# haltium_bbpr register map
Vendor: Nordic Semiconductor; Series: nRFHaltium; File version: 1
Registers are 32-bit, read-write, reset 0x0 unless marked. A register's access mark holds for its fields unless they carry their own. Offsets are from the block's base; [hi:lo] are bit positions; lines under a group give offsets from that group; {n}, {i} and the like mark numbered series; 'fields as' and 'values as' point back to an identical list.

## GLOBAL_I3CCORE0_NS (part 2 of 2) — I3CCORE 0
Base 0x2FBE0000
Same registers: GLOBAL_I3CCORE1_NS 0x2FBE1000, GLOBAL_I3CCORE2_NS 0x2FBE2000, GLOBAL_I3CCORE3_NS 0x2FBE3000
0x900 DMA group — Unspecified
  0x00 CH0 group — Unspecified
    0x00 SAR0 64-bit — This register contains the source address of the DMA transfer.
      [31:0] SAR — Current Source Address of DMA transfer.
    0x08 DAR0 64-bit — This register contains the destination address of the DMA transfer.
      [31:0] DAR — Current Destination address of DMA transfer.
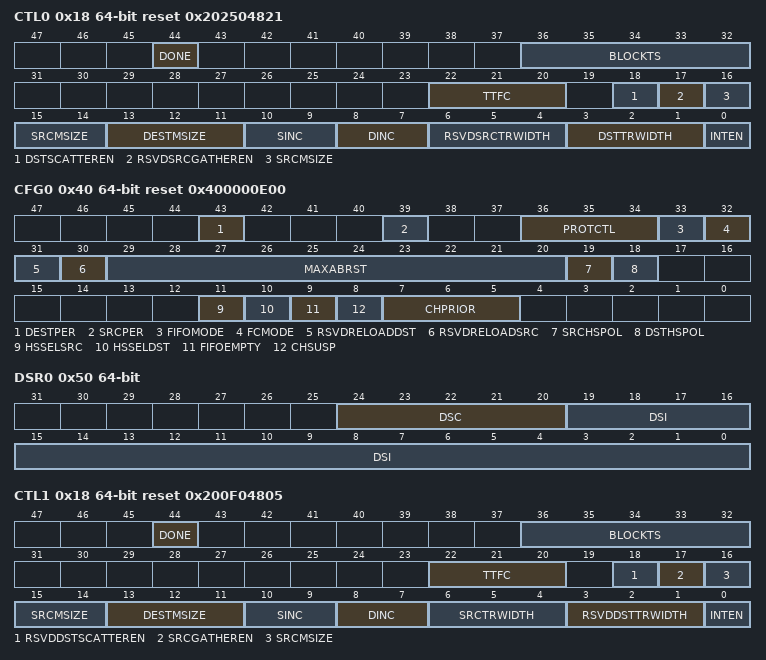
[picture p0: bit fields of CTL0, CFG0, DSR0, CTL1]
    0x18 CTL0 64-bit reset 0x202504821 (reset mask 0xFFFFFFFF) — This register contains fields that control the DMA transfer.
      [44] DONE — Done bit.
        0=DISABLED (Unspecified); 1=ENABLED (Unspecified)
      [36:32] BLOCKTS — Block Transfer Size.
      [22:20] TTFC — Transfer Type and Flow Control.
        {v}=TT_FC_{v} (Unspecified) (v=0..7)
      [18] DSTSCATTEREN — Destination scatter enable.
        0=DST_SCATTER_DISABLE (Unspecified); 1=DST_SCATTER_ENABLE (Unspecified)
      [17] RSVDSRCGATHEREN ro — Reserved field - read-only
      [16:14] SRCMSIZE — Source Burst Transaction Length.
        {v}=SRC_MSIZE_{v} (Unspecified) (v=0..7)
      [13:11] DESTMSIZE — Destination Burst Transaction Length.
        {v}=DEST_MSIZE_{v} (Unspecified) (v=0..7)
      [10:9] SINC — Source Address Increment.
        {v}=Unspecified (v=0..3)
      [8:7] DINC — Destination Address Increment.
        {v}=Unspecified (v=0..3)
      [6:4] RSVDSRCTRWIDTH ro — Reserved field - read-only
      [3:1] DSTTRWIDTH — Destination Transfer Width.
        {v}=DST_TR_WIDTH_{v} (Unspecified) (v=0..7)
      [0] INTEN — Interrupt Enable Bit.
        0=INTERRUPT_DISABLE (Unspecified); 1=INTERRUPT_ENABLE (Unspecified)
    0x40 CFG0 64-bit reset 0x400000E00 (reset mask 0xFFFFFFFF) — This register contains fields that configure the DMA transfer.
      [43] DESTPER — Destination hardware interface.
      [39] SRCPER — Source Hardware Interface.
      [36:34] PROTCTL — Protection Control bits used to drive the AHB HPROT[3:1] bus.
      [33] FIFOMODE — FIFO Mode Select.
        0=FIFO_MODE_0 (Unspecified); 1=FIFO_MODE_1 (Unspecified)
      [32] FCMODE — Flow Control Mode.
        0=Unspecified; 1=Unspecified
      [31] RSVDRELOADDST ro — Reserved field- read-only
      [30] RSVDRELOADSRC ro — Reserved field - read-only
      [29:20] MAXABRST — Maximum AMBA Burst Length.
      [19] SRCHSPOL — Source Handshaking Interface Polarity.
        0=ACTIVE_HIGH (Unspecified); 1=ACTIVE_LOW (Unspecified)
      [18] DSTHSPOL — Destination Handshaking Interface Polarity.
        0=ACTIVE_HIGH (Unspecified); 1=ACTIVE_LOW (Unspecified)
      [11] HSSELSRC — Source Software or Hardware Handshaking Select.
        0=HARDWARE_HS (Unspecified); 1=SOFTWARE_HS (Unspecified)
      [10] HSSELDST — Destination Software or Hardware Handshaking Select.
        0=HARDWARE_HS (Unspecified); 1=SOFTWARE_HS (Unspecified)
      [9] FIFOEMPTY ro — Channel FIFO status.
        0=NOT_EMPTY (Unspecified); 1=EMPTY (Unspecified)
      [8] CHSUSP — Channel Suspend.
        0=NOT_SUSPENDED (Unspecified); 1=SUSPENDED (Unspecified)
      [7:5] CHPRIOR — Channel Priority.
        {v}=CH_PRIOR_{v} (Unspecified) (v=0..7)
    0x50 DSR0 64-bit — Destination Scatter register.
      [24:20] DSC — Destination Scatter Count.
      [19:0] DSI — Destination Scatter Interval.
  0x58 CH1 group — Unspecified
    0x00 SAR1 64-bit — This register contains the source address of the DMA transfer.
      [31:0] SAR — Current Source Address of DMA transfer.
    0x08 DAR1 64-bit — This register contains the destination address of the DMA transfer.
      [31:0] DAR — Current Destination address of DMA transfer.
    0x18 CTL1 64-bit reset 0x200F04805 (reset mask 0xFFFFFFFF) — This register contains fields that control the DMA transfer.
      [44] DONE — Done bit.
        0=DISABLED (Unspecified); 1=ENABLED (Unspecified)
      [36:32] BLOCKTS — Block Transfer Size.
      [22:20] TTFC — Transfer Type and Flow Control.
        {v}=TT_FC_{v} (Unspecified) (v=0..7)
      [18] RSVDDSTSCATTEREN ro — Reserved field - read-only
      [17] SRCGATHEREN — Source gather enable.
        0=SRC_GATHER_DISABLE (Unspecified); 1=SRC_GATHER_ENABLE (Unspecified)
      [16:14] SRCMSIZE — Source Burst Transaction Length.
        {v}=SRC_MSIZE_{v} (Unspecified) (v=0..7)
      [13:11] DESTMSIZE — Destination Burst Transaction Length.
        {v}=DEST_MSIZE_{v} (Unspecified) (v=0..7)
      [10:9] SINC — Source Address Increment.
        {v}=Unspecified (v=0..3)
      [8:7] DINC — Destination Address Increment.
        {v}=Unspecified (v=0..3)
      [6:4] SRCTRWIDTH — Source Transfer Width.
        {v}=SRC_TR_WIDTH_{v} (Unspecified) (v=0..7)
      [3:1] RSVDDSTTRWIDTH ro — Reserved field - read-only
      [0] INTEN — Interrupt Enable Bit.
        values as DMA.CH0.CTL0.INTEN
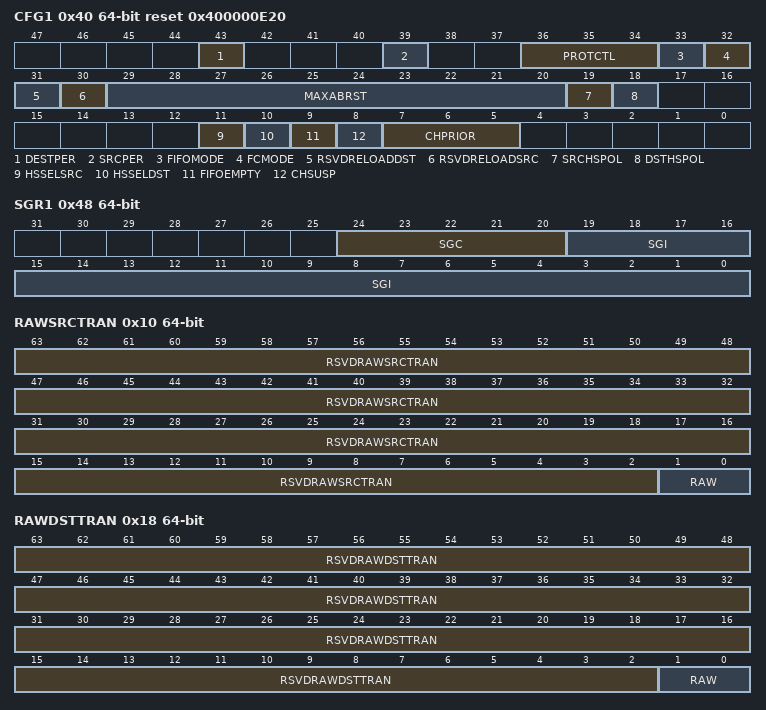
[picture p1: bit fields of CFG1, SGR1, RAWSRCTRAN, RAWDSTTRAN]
    0x40 CFG1 64-bit reset 0x400000E20 (reset mask 0xFFFFFFFF) — This register contains fields that configure the DMA transfer.
      fields as DMA.CH0.CFG0
    0x48 SGR1 64-bit — Source Gather register
      [24:20] SGC — Source Gather Count.
      [19:0] SGI — Source Gather Interval.
  0x2C0 INT group — Unspecified
    0x00 RAWTFR 64-bit — Interrupt events are stored in this Raw Interrupt Status register before masking.
      [1:0] RAW — Raw Status for IntTfr Interrupt
        0=INACTIVE (Unspecified); 1=ACTIVE (Unspecified)
    0x08 RAWBLOCK 64-bit — Interrupt events are stored in this Raw Interrupt Status register before masking.
      [1:0] RAW — Raw Status for IntBlock Interrupt
        0=INACTIVE (Unspecified); 1=ACTIVE (Unspecified)
    0x10 RAWSRCTRAN 64-bit (reset mask 0xFFFFFFFF) — Interrupt events are stored in this Raw Interrupt Status register before masking.
      [63:2] RSVDRAWSRCTRAN ro — Reserved field - read-only
      [1:0] RAW — Raw Status for IntSrcTran Interrupt
        0=INACTIVE (Unspecified); 1=ACTIVE (Unspecified)
    0x18 RAWDSTTRAN 64-bit (reset mask 0xFFFFFFFF) — Interrupt events are stored in this Raw Interrupt Status register before masking.
      [63:2] RSVDRAWDSTTRAN ro — Reserved field - read-only
      [1:0] RAW — Raw Status for IntDstTran Interrupt
        0=INACTIVE (Unspecified); 1=ACTIVE (Unspecified)
    0x20 RAWERR 64-bit — Interrupt events are stored in this Raw Interrupt Status register before masking.
      [1:0] RAW — Raw Status for IntErr Interrupt
        0=INACTIVE (Unspecified); 1=ACTIVE (Unspecified)
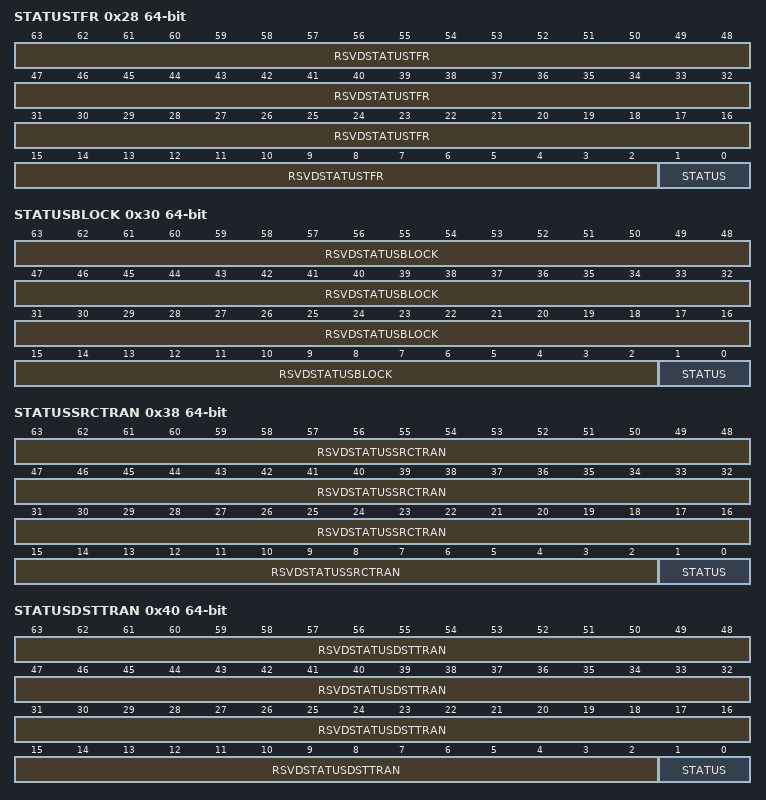
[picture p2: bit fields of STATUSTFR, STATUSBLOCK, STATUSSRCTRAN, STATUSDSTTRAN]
    0x28 STATUSTFR 64-bit (reset mask 0xFFFFFFFF) — Channel DMA Transfer complete interrupt event from all channels is stored in this Interrupt Status register after masking.
      [63:2] RSVDSTATUSTFR ro — Reserved field - read-only
      [1:0] STATUS ro — Status for IntTfr Interrupt
        0=INACTIVE (Unspecified); 1=ACTIVE (Unspecified)
    0x30 STATUSBLOCK 64-bit (reset mask 0xFFFFFFFF) — Channel Block complete interrupt event from all channels is stored in this Interrupt Status register after masking.
      [63:2] RSVDSTATUSBLOCK ro — Reserved field - read-only
      [1:0] STATUS ro — Status for IntBlock Interrupt
        0=INACTIVE (Unspecified); 1=ACTIVE (Unspecified)
    0x38 STATUSSRCTRAN 64-bit (reset mask 0xFFFFFFFF) — Channel Source Transaction complete interrupt event from all channels is stored in this Interrupt Status register after masking.
      [63:2] RSVDSTATUSSRCTRAN ro — Reserved field - read-only
      [1:0] STATUS ro — Status for IntSrcTran Interrupt
        0=INACTIVE (Unspecified); 1=ACTIVE (Unspecified)
    0x40 STATUSDSTTRAN 64-bit (reset mask 0xFFFFFFFF) — Channel destination transaction complete interrupt event from all channels is stored in this Interrupt Status register after masking.
      [63:2] RSVDSTATUSDSTTRAN ro — Reserved field - read-only
      [1:0] STATUS ro — Status for IntDstTran Interrupt
        0=INACTIVE (Unspecified); 1=ACTIVE (Unspecified)
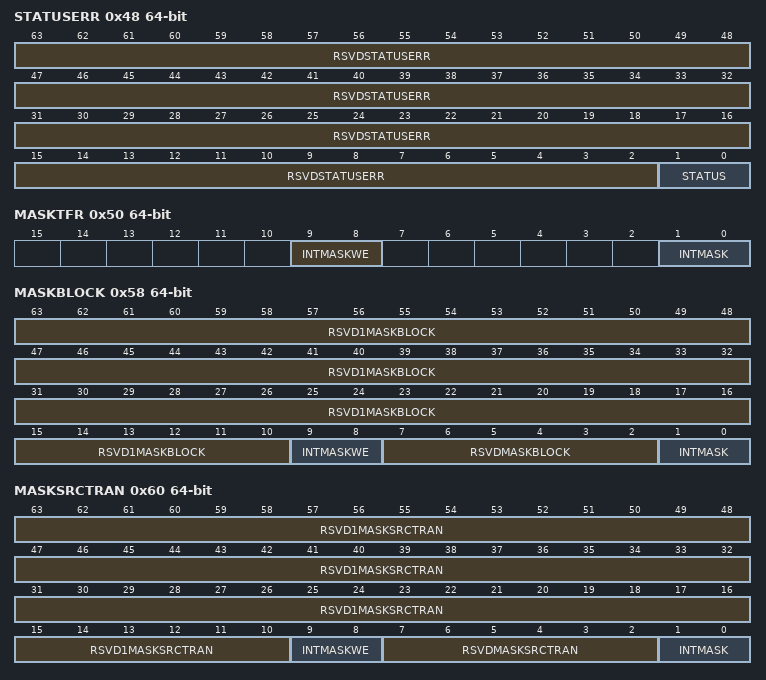
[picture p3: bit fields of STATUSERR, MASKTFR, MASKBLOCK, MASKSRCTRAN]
    0x48 STATUSERR 64-bit (reset mask 0xFFFFFFFF) — Channel Error interrupt event from all channels is stored in this Interrupt Status register after masking.
      [63:2] RSVDSTATUSERR ro — Reserved field - read-only
      [1:0] STATUS ro — Status for IntErr Interrupt
        0=INACTIVE (Unspecified); 1=ACTIVE (Unspecified)
    0x50 MASKTFR 64-bit — The contents of the Raw Status register RawTfr is masked with the contents of the Mask register MaskTfr.
      [9:8] INTMASKWE wo — Interrupt Mask Write Enable
        0=DISABLED (Unspecified); 1=ENABLED (Unspecified)
      [1:0] INTMASK — Mask for IntTfr Interrupt
        0=MASK (Unspecified); 1=UNMASK (Unspecified)
    0x58 MASKBLOCK 64-bit (reset mask 0xFFFFFFFF) — The contents of the Raw Status register RawBlock is masked with the contents of the Mask register MaskBlock.
      [63:10] RSVD1MASKBLOCK ro — Reserved field - read-only
      [9:8] INTMASKWE wo — Interrupt Mask Write Enable
        0=DISABLED (Unspecified); 1=ENABLED (Unspecified)
      [7:2] RSVDMASKBLOCK ro — Reserved field- read-only
      [1:0] INTMASK — Mask for IntBlock Interrupt
        0=MASK (Unspecified); 1=UNMASK (Unspecified)
    0x60 MASKSRCTRAN 64-bit (reset mask 0xFFFFFFFF) — The contents of the Raw Status register RawSrcTran is masked with the contents of the Mask register MaskSrcTran.
      [63:10] RSVD1MASKSRCTRAN ro — Reserved field - read-only
      [9:8] INTMASKWE wo — Interrupt Mask Write Enable
        0=DISABLED (Unspecified); 1=ENABLED (Unspecified)
      [7:2] RSVDMASKSRCTRAN ro — Reserved field- read-only
      [1:0] INTMASK — Mask for IntSrcTran Interrupt
        0=MASK (Unspecified); 1=UNMASK (Unspecified)
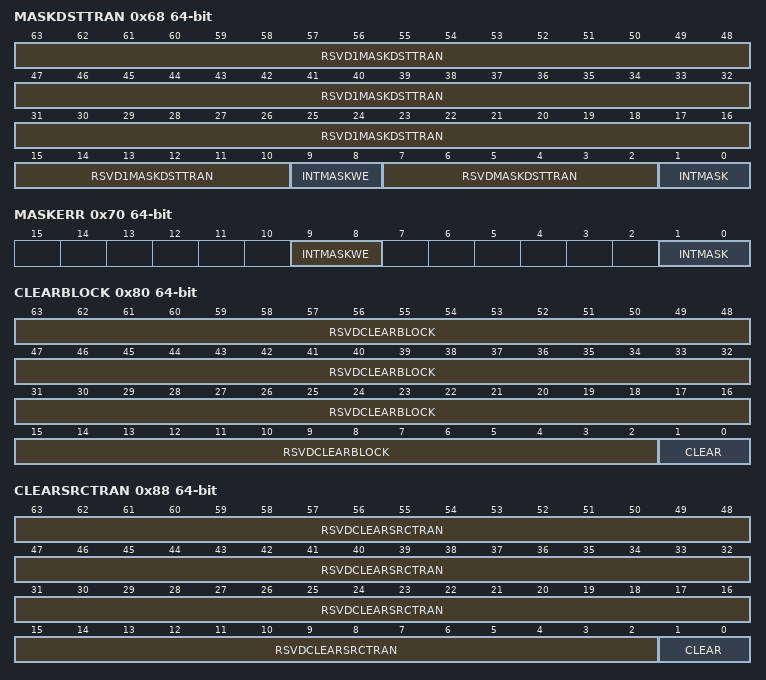
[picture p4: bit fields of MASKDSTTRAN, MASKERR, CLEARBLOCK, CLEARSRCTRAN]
    0x68 MASKDSTTRAN 64-bit (reset mask 0xFFFFFFFF) — The contents of the Raw Status register RawDstTran is masked with the contents of the Mask register MaskDstTran.
      [63:10] RSVD1MASKDSTTRAN ro — Reserved field - read-only
      [9:8] INTMASKWE wo — Interrupt Mask Write Enable
        0=DISABLED (Unspecified); 1=ENABLED (Unspecified)
      [7:2] RSVDMASKDSTTRAN ro — Reserved field - read-only
      [1:0] INTMASK — Mask for IntDstTran Interrupt
        0=MASK (Unspecified); 1=UNMASK (Unspecified)
    0x70 MASKERR 64-bit — The contents of the Raw Status register RawErr is masked with the contents of the Mask register MaskErr.
      [9:8] INTMASKWE wo — Interrupt Mask Write Enable
        0=DISABLED (Unspecified); 1=ENABLED (Unspecified)
      [1:0] INTMASK — Mask for IntErr Interrupt
        0=MASK (Unspecified); 1=UNMASK (Unspecified)
    0x78 CLEARTFR 64-bit — Each bit in the RawTfr and StatusTfr is cleared on the same cycle by writing a 1 to the corresponding location in the this registers.
      [1:0] CLEAR wo — Clear for IntTfr Interrupt
        0=NOT_CLEAR (Unspecified); 1=CLEAR (Unspecified)
    0x80 CLEARBLOCK 64-bit (reset mask 0xFFFFFFFF) — Each bit in the RawBlock and StatusBlock is cleared on the same cycle by writing a 1 to the corresponding location in the this registers.
      [63:2] RSVDCLEARBLOCK wo — Reserved field
      [1:0] CLEAR wo — Clear for IntBlock Interrupt
    0x88 CLEARSRCTRAN 64-bit (reset mask 0xFFFFFFFF) — Each bit in the RawSrcTran and StatusSrcTran is cleared on the same cycle by writing a 1 to the corresponding location in the this registers.
      [63:2] RSVDCLEARSRCTRAN wo — Reserved field
      [1:0] CLEAR wo — Clear for IntSrcTran Interrupt
        0=NOT_CLEAR (Unspecified); 1=CLEAR (Unspecified)
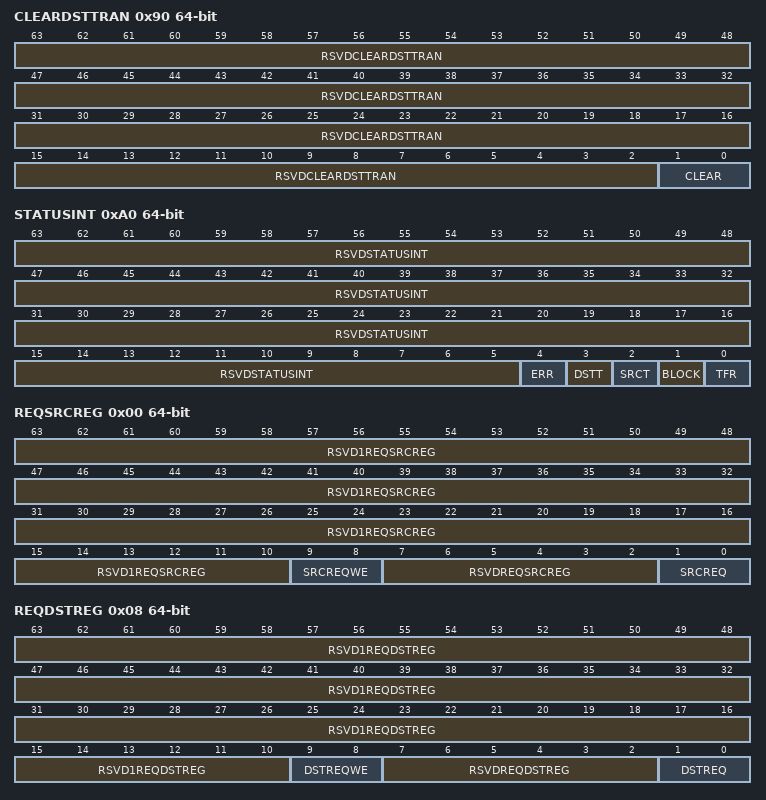
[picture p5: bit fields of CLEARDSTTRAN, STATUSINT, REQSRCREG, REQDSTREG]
    0x90 CLEARDSTTRAN 64-bit (reset mask 0xFFFFFFFF) — Each bit in the RawDstTran and StatusDstTran is cleared on the same cycle by writing a 1 to the corresponding location in the this registers.
      [63:2] RSVDCLEARDSTTRAN wo — Reserved field
      [1:0] CLEAR wo — Clear for IntDstTran Interrupt
        0=NOT_CLEAR (Unspecified); 1=CLEAR (Unspecified)
    0x98 CLEARERR 64-bit — Each bit in the RawErr and StatusErr is cleared on the same cycle by writing a 1 to the corresponding location in the this registers.
      [1:0] CLEAR wo — Clear for IntErr Interrupt
        0=NOT_CLEAR (Unspecified); 1=CLEAR (Unspecified)
    0xA0 STATUSINT 64-bit (reset mask 0xFFFFFFFF) — The contents of each of the five Status registers StatusTfr, StatusBlock, StatusSrcTran, StatusDstTran, StatusErr is ORed to produce a single bit for each interrupt type in the Combined Status register (StatusInt).
      [63:5] RSVDSTATUSINT ro — Reserved field- read-only
      [4] ERR ro — OR of the contents of StatusErr
        0=INACTIVE (Unspecified); 1=ACTIVE (Unspecified)
      [3] DSTT ro — OR of the contents of StatusDstTran
        0=INACTIVE (Unspecified); 1=ACTIVE (Unspecified)
      [2] SRCT ro — OR of the contents of StatusSrcTran
        0=INACTIVE (Unspecified); 1=ACTIVE (Unspecified)
      [1] BLOCK ro — OR of the contents of StatusBlock register
        0=INACTIVE (Unspecified); 1=ACTIVE (Unspecified)
      [0] TFR ro — OR of the contents of StatusTfr register
        0=INACTIVE (Unspecified); 1=ACTIVE (Unspecified)
  0x368 SWHANDSHAKE group — Unspecified
    0x00 REQSRCREG 64-bit (reset mask 0xFFFFFFFF) — A bit is assigned for each channel in this register.
      [63:10] RSVD1REQSRCREG ro — Reserved field - read-only
      [9:8] SRCREQWE wo — Source Software Transaction Request write enable
        0=DISABLED (Unspecified); 1=ENABLED (Unspecified)
      [7:2] RSVDREQSRCREG ro — Reserved field - read-only
      [1:0] SRCREQ — Source Software Transaction Request
        0=INACTIVE (Unspecified); 1=ACTIVE (Unspecified)
    0x08 REQDSTREG 64-bit (reset mask 0xFFFFFFFF) — A bit is assigned for each channel in this register.
      [63:10] RSVD1REQDSTREG ro — Reserved field - read-only
      [9:8] DSTREQWE wo — Destination Software Transaction Request write enable
        0=DISABLED (Unspecified); 1=ENABLED (Unspecified)
      [7:2] RSVDREQDSTREG ro — Reserved field - read-only
      [1:0] DSTREQ — Destination Software Transaction Request
        0=INACTIVE (Unspecified); 1=ACTIVE (Unspecified)
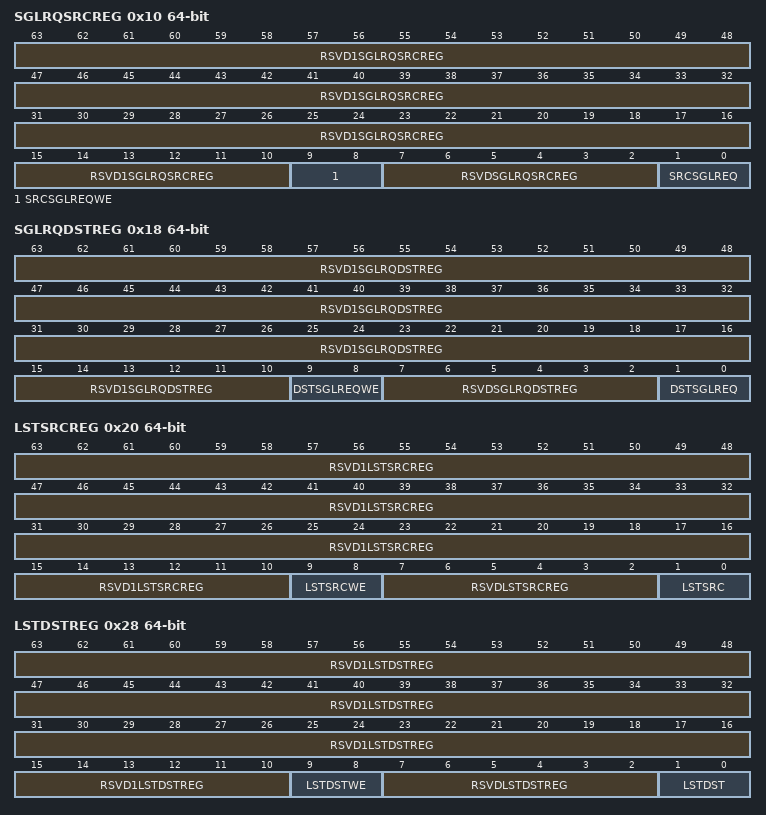
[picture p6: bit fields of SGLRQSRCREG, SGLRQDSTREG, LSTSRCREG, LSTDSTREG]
    0x10 SGLRQSRCREG 64-bit (reset mask 0xFFFFFFFF) — A bit is assigned for each channel in this register.
      [63:10] RSVD1SGLRQSRCREG ro — Reserved field - read-only
      [9:8] SRCSGLREQWE wo — Source Single Transaction Request write enable
        0=DISABLED (Unspecified); 1=ENABLED (Unspecified)
      [7:2] RSVDSGLRQSRCREG ro — Reserved field - read-only
      [1:0] SRCSGLREQ — Source Single Transaction Request
        0=INACTIVE (Unspecified); 1=ACTIVE (Unspecified)
    0x18 SGLRQDSTREG 64-bit (reset mask 0xFFFFFFFF) — A bit is assigned for each channel in this register.
      [63:10] RSVD1SGLRQDSTREG ro — Reserved field - read-only
      [9:8] DSTSGLREQWE wo — Destination Single Transaction Request write enable
        0=DISABLED (Unspecified); 1=ENABLED (Unspecified)
      [7:2] RSVDSGLRQDSTREG ro — Reserved field - read-only
      [1:0] DSTSGLREQ — Destination Single Transaction Request
        0=INACTIVE (Unspecified); 1=ACTIVE (Unspecified)
    0x20 LSTSRCREG 64-bit (reset mask 0xFFFFFFFF) — A bit is assigned for each channel in this register.
      [63:10] RSVD1LSTSRCREG ro — Reserved field- read-only
      [9:8] LSTSRCWE wo — Source Last Transaction Request write enable
        0=DISABLED (Unspecified); 1=ENABLED (Unspecified)
      [7:2] RSVDLSTSRCREG ro — Reserved field- read-only
      [1:0] LSTSRC — Source Last Transaction Request register
        0=NOT_LAST (Unspecified); 1=LAST (Unspecified)
    0x28 LSTDSTREG 64-bit (reset mask 0xFFFFFFFF) — A bit is assigned for each channel in this register.
      [63:10] RSVD1LSTDSTREG ro — Reserved field - read-only
      [9:8] LSTDSTWE wo — Source Last Transaction Request write enable
        0=DISABLED (Unspecified); 1=ENABLED (Unspecified)
      [7:2] RSVDLSTDSTREG ro — Reserved field - read-only
      [1:0] LSTDST — Destination Last Transaction Request
        0=NOT_LAST (Unspecified); 1=LAST (Unspecified)
  0x398 MISC group — Unspecified
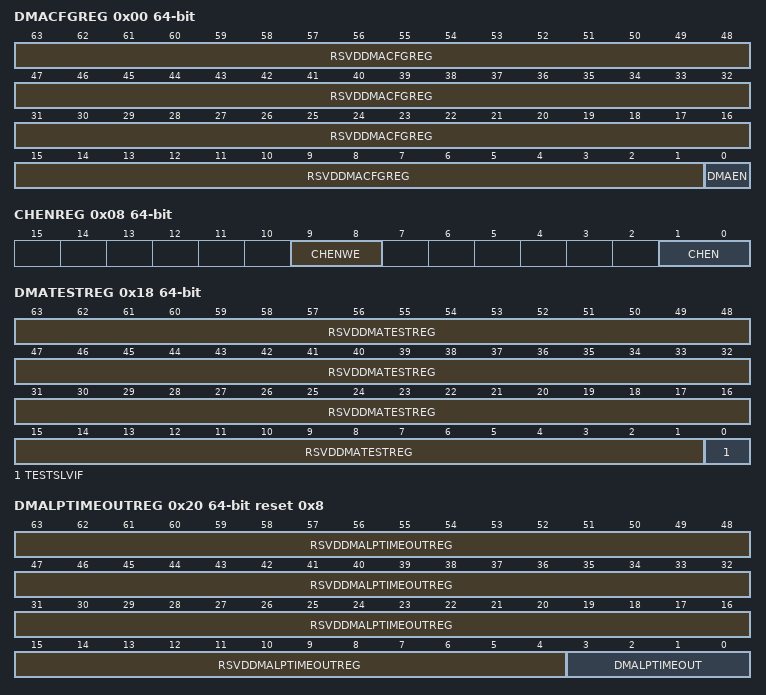
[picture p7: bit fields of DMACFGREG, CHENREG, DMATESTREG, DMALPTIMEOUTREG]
    0x00 DMACFGREG 64-bit (reset mask 0xFFFFFFFF) — This register is used to enable the DW_ahb_dmac, which must be done before any channel activity can begin.
      [63:1] RSVDDMACFGREG ro — Reserved field - read-only
      [0] DMAEN — DW_ahb_dmac Enable bit.
        0=DISABLED (Unspecified); 1=ENABLED (Unspecified)
    0x08 CHENREG 64-bit — This is the DW_ahb_dmac Channel Enable Register.
      [9:8] CHENWE wo — Channel enable register
      [1:0] CHEN — Channel Enable.
        0=DISABLED (Unspecified); 1=ENABLED (Unspecified)
    0x10 DMAIDREG 64-bit — This is the DW_ahb_dmac ID register, which is a read-only register that reads back the coreConsultant-configured hardcoded ID number, DMAH_ID_NUM.
      [31:0] DMAID ro — Hardcoded DW_ahb_dmac peripheral ID.
    0x18 DMATESTREG 64-bit (reset mask 0xFFFFFFFF) — This register is used to put the AHB slave interface into test mode, during which the readback value of the writable registers match the value written, assuming the DW_ahb_dmac configuration has not optimized the same registers.
      [63:1] RSVDDMATESTREG ro — Reserved field- read-only
      [0] TESTSLVIF — DMA Test register
        0=NORMAL_MODE (Unspecified); 1=TEST_MODE (Unspecified)
    0x20 DMALPTIMEOUTREG 64-bit reset 0x8 (reset mask 0xFFFFFFFF) — This register holds the timeout value of Low Power Counter.
      [63:4] RSVDDMALPTIMEOUTREG ro — Reserved field - read-only
      [3:0] DMALPTIMEOUT — This field holds timeout value of low power counter register.
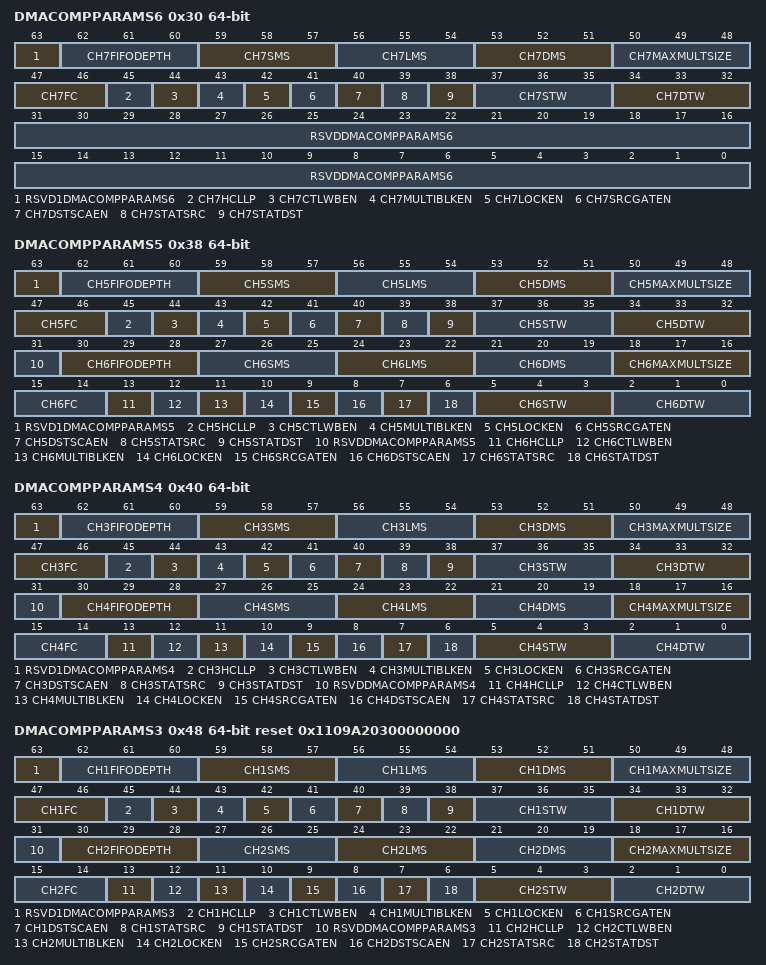
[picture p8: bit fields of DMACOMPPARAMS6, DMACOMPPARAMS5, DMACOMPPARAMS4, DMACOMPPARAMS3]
    0x30 DMACOMPPARAMS6 64-bit (reset mask 0xFFFFFFFF) — DMA_COMP_PARAMS_6 is a constant read-only register that contains encoded information about the component parameter settings for Channel 7.
      [63] RSVD1DMACOMPPARAMS6 ro — Reserved field- read-only
      [62:60] CH7FIFODEPTH ro — The value of this register is derived from the DMAH_CH7_FIFO_DEPTH coreConsultant parameter.
        0=FIFO_DEPTH_8 (Unspecified); 1=FIFO_DEPTH_16 (Unspecified); 2=FIFO_DEPTH_32 (Unspecified); 3=FIFO_DEPTH_64 (Unspecified); 4=FIFO_DEPTH_128 (Unspecified); 5=FIFO_DEPTH_256 (Unspecified)
      [59:57] CH7SMS ro — The value of this register is derived from the DMAH_CH7_SMS coreConsultant parameter.
        {v}=MASTER_{v+1} (Unspecified) (v=0..3); 4=PROGRAMMABLE (Unspecified)
      [56:54] CH7LMS ro — The value of this register is derived from the DMAH_CH7_LMS coreConsultant parameter.
        values as CH7SMS
      [53:51] CH7DMS ro — The value of this register is derived from the DMAH_CH7_DMS coreConsultant parameter.
        values as CH7SMS
      [50:48] CH7MAXMULTSIZE ro — The value of this register is derived from the DMAH_CH7_MULT_SIZE coreConsultant parameter.
        0=MAX_MULT_SIZE_4 (Unspecified); 1=MAX_MULT_SIZE_8 (Unspecified); 2=MAX_MULT_SIZE_16 (Unspecified); 3=MAX_MULT_SIZE_32 (Unspecified); 4=MAX_MULT_SIZE_64 (Unspecified); 5=MAX_MULT_SIZE_128 (Unspecified); 6=MAX_MULT_SIZE_256 (Unspecified)
      [47:46] CH7FC ro — The value of this register is derived from the DMAH_CH7_FC coreConsultant parameter.
        0=FC_DMA (Unspecified); 1=FC_SRC (Unspecified); 2=FC_DST (Unspecified); 3=FC_ANY (Unspecified)
      [45] CH7HCLLP ro — The value of this register is derived from the DMAH_CH7_HC_LLP coreConsultant parameter.
        0=HARDCODED (Unspecified); 0=PROGRAMMABLE (Unspecified)
      [44] CH7CTLWBEN ro — The value of this register is derived from the DMAH_CH7_CTL_WB_EN coreConsultant parameter.
        0=FALSE (Unspecified); 1=TRUE (Unspecified)
      [43] CH7MULTIBLKEN ro — The value of this register is derived from the DMAH_CH7_MULTI_BLK_EN coreConsultant parameter.
        0=FALSE (Unspecified); 1=TRUE (Unspecified)
      [42] CH7LOCKEN ro — The value of this register is derived from the DMAH_CH7_LOCK_EN coreConsultant parameter.
        0=FALSE (Unspecified); 1=TRUE (Unspecified)
      [41] CH7SRCGATEN ro — The value of this register is derived from the DMAH_CH7_SRC_GAT_EN coreConsultant parameter.
        0=FALSE (Unspecified); 1=TRUE (Unspecified)
      [40] CH7DSTSCAEN ro — The value of this register is derived from the DMAH_CH7_DST_SCA_EN coreConsultant parameter.
        0=FALSE (Unspecified); 1=TRUE (Unspecified)
      [39] CH7STATSRC ro — The value of this register is derived from the DMAH_CH7_STAT_SRC coreConsultant parameter.
        0=FALSE (Unspecified); 1=TRUE (Unspecified)
      [38] CH7STATDST ro — The value of this register is derived from the DMAH_CH7_STAT_DST coreConsultant parameter.
        0=FALSE (Unspecified); 1=TRUE (Unspecified)
      [37:35] CH7STW ro — The value of this register is derived from the DMAH_CH7_STW coreConsultant parameter.
        0=NO_HARDCODE (Unspecified); 1=STW_8 (Unspecified); 2=STW_16 (Unspecified); 3=STW_32 (Unspecified); 4=STW_64 (Unspecified); 5=STW_128 (Unspecified); 6=STW_256 (Unspecified)
      [34:32] CH7DTW ro — The value of this register is derived from the DMAH_CH7_DTW coreConsultant parameter.
        0=NO_HARDCODE (Unspecified); 1=DTW_8 (Unspecified); 2=DTW_16 (Unspecified); 3=DTW_32 (Unspecified); 4=DTW_64 (Unspecified); 5=DTW_128 (Unspecified); 6=DTW_256 (Unspecified)
      [31:0] RSVDDMACOMPPARAMS6 ro — Reserved field - read-only
    0x38 DMACOMPPARAMS5 64-bit (reset mask 0xFFFFFFFF) — DMA_COMP_PARAMS_5 is a constant read-only register that contains encoded information about the component parameter settings for Channel 5 and Channel 6.
      [63] RSVD1DMACOMPPARAMS5 ro — Reserved field- read-only
      [62:60] CH5FIFODEPTH ro — The value of this register is derived from the DMAH_CH5_FIFO_DEPTH coreConsultant parameter.
        values as DMA.MISC.DMACOMPPARAMS6.CH7FIFODEPTH
      [59:57] CH5SMS ro — The value of this register is derived from the DMAH_CH5_SMS coreConsultant parameter.
        values as DMA.MISC.DMACOMPPARAMS6.CH7SMS
      [56:54] CH5LMS ro — The value of this register is derived from the DMAH_CH5_LMS coreConsultant parameter.
        values as DMA.MISC.DMACOMPPARAMS6.CH7SMS
      [53:51] CH5DMS ro — The value of this register is derived from the DMAH_CH5_DMS coreConsultant parameter.
        values as DMA.MISC.DMACOMPPARAMS6.CH7SMS
      [50:48] CH5MAXMULTSIZE ro — The value of this register is derived from the DMAH_CH5_MULT_SIZE coreConsultant parameter.
        values as DMA.MISC.DMACOMPPARAMS6.CH7MAXMULTSIZE
      [47:46] CH5FC ro — The value of this register is derived from the DMAH_CH5_FC coreConsultant parameter.
        values as DMA.MISC.DMACOMPPARAMS6.CH7FC
      [45] CH5HCLLP ro — The value of this register is derived from the DMAH_CH5_HC_LLP coreConsultant parameter.
        0=HARDCODED (Unspecified); 0=PROGRAMMABLE (Unspecified)
      [44] CH5CTLWBEN ro — The value of this register is derived from the DMAH_CH5_CTL_WB_EN coreConsultant parameter.
        0=FALSE (Unspecified); 1=TRUE (Unspecified)
      [43] CH5MULTIBLKEN ro — The value of this register is derived from the DMAH_CH5_MULTI_BLK_EN coreConsultant parameter.
        0=FALSE (Unspecified); 1=TRUE (Unspecified)
      [42] CH5LOCKEN ro — The value of this register is derived from the DMAH_CH5_LOCK_EN coreConsultant parameter.
        0=FALSE (Unspecified); 1=TRUE (Unspecified)
      [41] CH5SRCGATEN ro — The value of this register is derived from the DMAH_CH5_SRC_GAT_EN coreConsultant parameter.
        0=FALSE (Unspecified); 1=TRUE (Unspecified)
      [40] CH5DSTSCAEN ro — The value of this register is derived from the DMAH_CH5_DST_SCA_EN coreConsultant parameter.
        0=FALSE (Unspecified); 1=TRUE (Unspecified)
      [39] CH5STATSRC ro — The value of this register is derived from the DMAH_CH5_STAT_SRC coreConsultant parameter.
        0=FALSE (Unspecified); 1=TRUE (Unspecified)
      [38] CH5STATDST ro — The value of this register is derived from the DMAH_CH5_STAT_DST coreConsultant parameter.
        0=FALSE (Unspecified); 1=TRUE (Unspecified)
      [37:35] CH5STW ro — The value of this register is derived from the DMAH_CH5_STW coreConsultant parameter.
        0=TRANS_WIDTH_PROGRAMMABLE (Unspecified); 1=TRANS_WIDTH_8 (Unspecified); 2=TRANS_WIDTH_16 (Unspecified); 3=TRANS_WIDTH_32 (Unspecified); 4=TRANS_WIDTH_64 (Unspecified); 5=TRANS_WIDTH_128 (Unspecified); 6=TRANS_WIDTH_256 (Unspecified)
      [34:32] CH5DTW ro — The value of this register is derived from the DMAH_CH5_DTW coreConsultant parameter.
        values as CH5STW
      [31] RSVDDMACOMPPARAMS5 ro — Reserved field- read-only
      [30:28] CH6FIFODEPTH ro — The value of this register is derived from the DMAH_CH6_FIFO_DEPTH coreConsultant parameter.
        0=IFO_DEPTH_8 (Unspecified); 1=FIFO_DEPTH_16 (Unspecified); 2=FIFO_DEPTH_32 (Unspecified); 3=FIFO_DEPTH_64 (Unspecified); 4=FIFO_DEPTH_128 (Unspecified); 5=FIFO_DEPTH_256 (Unspecified)
      [27:25] CH6SMS ro — The value of this register is derived from the DMAH_CH6_SMS coreConsultant parameter.
        values as DMA.MISC.DMACOMPPARAMS6.CH7SMS
      [24:22] CH6LMS ro — The value of this register is derived from the DMAH_CH6_LMS coreConsultant parameter.
        values as DMA.MISC.DMACOMPPARAMS6.CH7SMS
      [21:19] CH6DMS ro — The value of this register is derived from the DMAH_CH6_DMS coreConsultant parameter.
        values as DMA.MISC.DMACOMPPARAMS6.CH7SMS
      [18:16] CH6MAXMULTSIZE ro — The value of this register is derived from the DMAH_CH6_MULT_SIZE coreConsultant parameter.
        values as DMA.MISC.DMACOMPPARAMS6.CH7MAXMULTSIZE
      [15:14] CH6FC ro — The value of this register is derived from the DMAH_CH6_FC coreConsultant parameter.
        values as DMA.MISC.DMACOMPPARAMS6.CH7FC
      [13] CH6HCLLP ro — The value of this register is derived from the DMAH_CH6_HC_LLP coreConsultant parameter.
        0=HARDCODED (Unspecified); 0=PROGRAMMABLE (Unspecified)
      [12] CH6CTLWBEN ro — The value of this register is derived from the DMAH_CH6_CTL_WB_EN coreConsultant parameter.
        0=FALSE (Unspecified); 1=TRUE (Unspecified)
      [11] CH6MULTIBLKEN ro — The value of this register is derived from the DMAH_CH6_MULTI_BLK_EN coreConsultant parameter.
        0=FALSE (Unspecified); 1=TRUE (Unspecified)
      [10] CH6LOCKEN ro — The value of this register is derived from the DMAH_CH6_LOCK_EN coreConsultant parameter.
        0=FALSE (Unspecified); 1=TRUE (Unspecified)
      [9] CH6SRCGATEN ro — The value of this register is derived from the CH6_SRC_GAT_EN coreConsultant parameter.
        0=FALSE (Unspecified); 1=TRUE (Unspecified)
      [8] CH6DSTSCAEN ro — The value of this register is derived from the DMAH_CH6_DST_SCA_EN coreConsultant parameter.
        0=FALSE (Unspecified); 1=TRUE (Unspecified)
      [7] CH6STATSRC ro — The value of this register is derived from the DMAH_CH6_STAT_SRC coreConsultant parameter.
        0=FALSE (Unspecified); 1=TRUE (Unspecified)
      [6] CH6STATDST ro — The value of this register is derived from the DMAH_CH6_STAT_DST coreConsultant parameter.
        0=FALSE (Unspecified); 1=TRUE (Unspecified)
      [5:3] CH6STW ro — The value of this register is derived from the DMAH_CH6_STW coreConsultant parameter.
        values as CH5STW
      [2:0] CH6DTW ro — The value of this register is derived from the DMAH_CH6_DTW coreConsultant parameter.
        values as CH5STW
    0x40 DMACOMPPARAMS4 64-bit (reset mask 0xFFFFFFFF) — DMA_COMP_PARAMS_4 is a constant read-only register that contains encoded information about the component parameter settings for Channel 3 and Channel 4.
      [63] RSVD1DMACOMPPARAMS4 ro — Reserved field- read-only
      [62:60] CH3FIFODEPTH ro — The value of this register is derived from the DMAH_CH3_FIFO_DEPTH coreConsultant parameter.
        values as DMA.MISC.DMACOMPPARAMS6.CH7FIFODEPTH
      [59:57] CH3SMS ro — The value of this register is derived from the DMAH_CH3_SMS coreConsultant parameter.
        values as DMA.MISC.DMACOMPPARAMS6.CH7SMS
      [56:54] CH3LMS ro — The value of this register is derived from the DMAH_CH3_LMS coreConsultant parameter.
        values as DMA.MISC.DMACOMPPARAMS6.CH7SMS
      [53:51] CH3DMS ro — The value of this register is derived from the DMAH_CH3_DMS coreConsultant parameter.
        values as DMA.MISC.DMACOMPPARAMS6.CH7SMS
      [50:48] CH3MAXMULTSIZE ro — The value of this register is derived from the DMAH_CH3_MULT_SIZE coreConsultant parameter.
        values as DMA.MISC.DMACOMPPARAMS6.CH7MAXMULTSIZE
      [47:46] CH3FC ro — The value of this register is derived from the DMAH_CH3_FC coreConsultant parameter.
        values as DMA.MISC.DMACOMPPARAMS6.CH7FC
      [45] CH3HCLLP ro — The value of this register is derived from the DMAH_CH3_HC_LLP coreConsultant parameter.
        0=HARDCODED (Unspecified); 0=PROGRAMMABLE (Unspecified)
      [44] CH3CTLWBEN ro — The value of this register is derived from the DMAH_CH3_CTL_WB_EN coreConsultant parameter.
        0=FALSE (Unspecified); 1=TRUE (Unspecified)
      [43] CH3MULTIBLKEN ro — The value of this register is derived from the DMAH_CH3_MULTI_BLK_EN coreConsultant parameter.
        0=FALSE (Unspecified); 1=TRUE (Unspecified)
      [42] CH3LOCKEN ro — The value of this register is derived from the DMAH_CH3_LOCK_EN coreConsultant parameter.
        0=FALSE (Unspecified); 1=TRUE (Unspecified)
      [41] CH3SRCGATEN ro — The value of this register is derived from the DMAH_CH3_SRC_GAT_EN coreConsultant parameter.
        0=FALSE (Unspecified); 1=TRUE (Unspecified)
      [40] CH3DSTSCAEN ro — The value of this register is derived from the DMAH_CH3_DST_SCA_EN coreConsultant parameter.
        0=FALSE (Unspecified); 1=TRUE (Unspecified)
      [39] CH3STATSRC ro — The value of this register is derived from the DMAH_CH3_STAT_SRC coreConsultant parameter.
        0=FALSE (Unspecified); 1=TRUE (Unspecified)
      [38] CH3STATDST ro — The value of this register is derived from the DMAH_CH3_STAT_DST coreConsultant parameter.
        0=FALSE (Unspecified); 1=TRUE (Unspecified)
      [37:35] CH3STW ro — The value of this register is derived from the DMAH_CH3_STW coreConsultant parameter.
        values as DMA.MISC.DMACOMPPARAMS5.CH5STW
      [34:32] CH3DTW ro — The value of this register is derived from the DMAH_CH3_DTW coreConsultant parameter.
        values as DMA.MISC.DMACOMPPARAMS5.CH5STW
      [31] RSVDDMACOMPPARAMS4 ro — Reserved field- read-only
      [30:28] CH4FIFODEPTH ro — The value of this register is derived from the DMAH_CH4_FIFO_DEPTH coreConsultant parameter.
        values as DMA.MISC.DMACOMPPARAMS6.CH7FIFODEPTH
      [27:25] CH4SMS ro — The value of this register is derived from the DMAH_CH4_SMS coreConsultant parameter.
        values as DMA.MISC.DMACOMPPARAMS6.CH7SMS
      [24:22] CH4LMS ro — The value of this register is derived from the DMAH_CH4_LMS coreConsultant parameter.
        values as DMA.MISC.DMACOMPPARAMS6.CH7SMS
      [21:19] CH4DMS ro — The value of this register is derived from the DMAH_CH4_DMS coreConsultant parameter.
        values as DMA.MISC.DMACOMPPARAMS6.CH7SMS
      [18:16] CH4MAXMULTSIZE ro — The value of this register is derived from the DMAH_CH4_MULT_SIZE coreConsultant parameter.
        values as DMA.MISC.DMACOMPPARAMS6.CH7MAXMULTSIZE
      [15:14] CH4FC ro — The value of this register is derived from the DMAH_CH4_FC coreConsultant parameter.
        values as DMA.MISC.DMACOMPPARAMS6.CH7FC
      [13] CH4HCLLP ro — The value of this register is derived from the DMAH_CH4_HC_LLP coreConsultant parameter.
        0=HARDCODED (Unspecified); 0=PROGRAMMABLE (Unspecified)
      [12] CH4CTLWBEN ro — The value of this register is derived from the DMAH_CH4_CTL_WB_EN coreConsultant parameter.
        0=FALSE (Unspecified); 1=TRUE (Unspecified)
      [11] CH4MULTIBLKEN ro — The value of this register is derived from the DMAH_CH4_MULTI_BLK_EN coreConsultant parameter.
        0=FALSE (Unspecified); 1=TRUE (Unspecified)
      [10] CH4LOCKEN ro — The value of this register is derived from the DMAH_CH4_LOCK_EN coreConsultant parameter.
        0=FALSE (Unspecified); 1=TRUE (Unspecified)
      [9] CH4SRCGATEN ro — The value of this register is derived from the DMAH_CH4_SRC_GAT_EN coreConsultant parameter.
        0=FALSE (Unspecified); 1=TRUE (Unspecified)
      [8] CH4DSTSCAEN ro — The value of this register is derived from the DMAH_CH4_DST_SCA_EN coreConsultant parameter.
        0=FALSE (Unspecified); 1=TRUE (Unspecified)
      [7] CH4STATSRC ro — The value of this register is derived from the DMAH_CH4_STAT_SRC coreConsultant parameter.
        0=FALSE (Unspecified); 1=TRUE (Unspecified)
      [6] CH4STATDST ro — The value of this register is derived from the DMAH_CH4_STAT_DST coreConsultant parameter.
        0=FALSE (Unspecified); 1=TRUE (Unspecified)
      [5:3] CH4STW ro — The value of this register is derived from the DMAH_CH4_STW coreConsultant parameter.
        values as DMA.MISC.DMACOMPPARAMS5.CH5STW
      [2:0] CH4DTW ro — The value of this register is derived from the DMAH_CH4_DTW coreConsultant parameter.
        values as DMA.MISC.DMACOMPPARAMS5.CH5STW
    0x48 DMACOMPPARAMS3 64-bit reset 0x1109A20300000000 (reset mask 0xFFFFFFFF) — DMA_COMP_PARAMS_3 is a constant read-only register that contains encoded information about the component parameter settings for Channel 1 and Channel 2.
      [63] RSVD1DMACOMPPARAMS3 ro — Reserved field- read-only
      [62:60] CH1FIFODEPTH ro — The value of this register is derived from the DMAH_CH1_FIFO_DEPTH coreConsultant parameter.
        values as DMA.MISC.DMACOMPPARAMS6.CH7FIFODEPTH
      [59:57] CH1SMS ro — The value of this register is derived from the DMAH_CH1_SMS coreConsultant parameter.
        values as DMA.MISC.DMACOMPPARAMS6.CH7SMS
      [56:54] CH1LMS ro — The value of this register is derived from the DMAH_CH1_LMS coreConsultant parameter.
        values as DMA.MISC.DMACOMPPARAMS6.CH7SMS
      [53:51] CH1DMS ro — The value of this register is derived from the DMAH_CH1_DMS coreConsultant parameter.
        values as DMA.MISC.DMACOMPPARAMS6.CH7SMS
      [50:48] CH1MAXMULTSIZE ro — The value of this register is derived from the DMAH_CH1_MULT_SIZE coreConsultant parameter.
        values as DMA.MISC.DMACOMPPARAMS6.CH7MAXMULTSIZE
      [47:46] CH1FC ro — The value of this register is derived from the DMAH_CH1_FC coreConsultant parameter.
        values as DMA.MISC.DMACOMPPARAMS6.CH7FC
      [45] CH1HCLLP ro — The value of this register is derived from the DMAH_CH1_HC_LLP coreConsultant parameter.
        0=HARDCODED (Unspecified); 0=PROGRAMMABLE (Unspecified)
      [44] CH1CTLWBEN ro — The value of this register is derived from the DMAH_CH1_CTL_WB_EN coreConsultant parameter.
        0=FALSE (Unspecified); 1=TRUE (Unspecified)
      [43] CH1MULTIBLKEN ro — The value of this register is derived from the DMAH_CH1_MULTI_BLK_EN coreConsultant parameter.
        0=FALSE (Unspecified); 1=TRUE (Unspecified)
      [42] CH1LOCKEN ro — The value of this register is derived from the DMAH_CH1_LOCK_EN coreConsultant parameter.
        0=FALSE (Unspecified); 1=TRUE (Unspecified)
      [41] CH1SRCGATEN ro — The value of this register is derived from the DMAH_CH1_SRC_GAT_EN coreConsultant parameter.
        0=FALSE (Unspecified); 1=TRUE (Unspecified)
      [40] CH1DSTSCAEN ro — The value of this register is derived from the DMAH_CH1_DST_SCA_EN coreConsultant parameter.
        0=FALSE (Unspecified); 1=TRUE (Unspecified)
      [39] CH1STATSRC ro — The value of this register is derived from the DMAH_CH1_STAT_SRC coreConsultant parameter.
        0=FALSE (Unspecified); 1=TRUE (Unspecified)
      [38] CH1STATDST ro — The value of this register is derived from the DMAH_CH1_STAT_DST coreConsultant parameter.
        0=FALSE (Unspecified); 1=TRUE (Unspecified)
      [37:35] CH1STW ro — The value of this register is derived from the DMAH_CH1_STW coreConsultant parameter.
        values as DMA.MISC.DMACOMPPARAMS5.CH5STW
      [34:32] CH1DTW ro — The value of this register is derived from the DMAH_CH1_DTW coreConsultant parameter.
        values as DMA.MISC.DMACOMPPARAMS5.CH5STW
      [31] RSVDDMACOMPPARAMS3 ro — Reserved field- read-only
      [30:28] CH2FIFODEPTH ro — The value of this register is derived from the DMAH_CH2_FIFO_DEPTH coreConsultant parameter.
        values as DMA.MISC.DMACOMPPARAMS6.CH7FIFODEPTH
      [27:25] CH2SMS ro — The value of this register is derived from the DMAH_CH2_SMS coreConsultant parameter.
        {v}=MASTER_{v+1} (Unspecified) (v=0..3); 4=PROGRAMMALE (Unspecified)
      [24:22] CH2LMS ro — The value of this register is derived from the DMAH_CH2_LMS coreConsultant parameter.
        values as CH2SMS
      [21:19] CH2DMS ro — The value of this register is derived from the DMAH_CH2_DMS coreConsultant parameter.
        values as DMA.MISC.DMACOMPPARAMS6.CH7SMS
      [18:16] CH2MAXMULTSIZE ro — The value of this register is derived from the DMAH_CH2_MULT_SIZE coreConsultant parameter.
        values as DMA.MISC.DMACOMPPARAMS6.CH7MAXMULTSIZE
      [15:14] CH2FC ro — The value of this register is derived from the DMAH_CH2_FC coreConsultant parameter.
        values as DMA.MISC.DMACOMPPARAMS6.CH7FC
      [13] CH2HCLLP ro — The value of this register is derived from the DMAH_CH2_HC_LLP coreConsultant parameter.
        0=HARDCODED (Unspecified); 0=PROGRAMMABLE (Unspecified)
      [12] CH2CTLWBEN ro — The value of this register is derived from the DMAH_CH2_CTL_WB_EN coreConsultant parameter.
        0=FALSE (Unspecified); 1=TRUE (Unspecified)
      [11] CH2MULTIBLKEN ro — The value of this register is derived from the DMAH_CH2_MULTI_BLK_EN coreConsultant parameter.
        0=FALSE (Unspecified); 1=TRUE (Unspecified)
      [10] CH2LOCKEN ro — The value of this register is derived from the DMAH_CH2_LOCK_EN coreConsultant parameter.
        0=FALSE (Unspecified); 1=TRUE (Unspecified)
      [9] CH2SRCGATEN ro — The value of this register is derived from the DMAH_CH2_SRC_GAT_EN coreConsultant parameter.
        0=FALSE (Unspecified); 1=TRUE (Unspecified)
      [8] CH2DSTSCAEN ro — The value of this register is derived from the DMAH_CH2_DST_SCA_EN coreConsultant parameter.
        0=FALSE (Unspecified); 1=TRUE (Unspecified)
      [7] CH2STATSRC ro — The value of this register is derived from the DMAH_CH2_STAT_SRC coreConsultant parameter.
        0=FALSE (Unspecified); 1=TRUE (Unspecified)
      [6] CH2STATDST ro — The value of this register is derived from the DMAH_CH2_STAT_DST coreConsultant parameter.
        0=FALSE (Unspecified); 1=TRUE (Unspecified)
      [5:3] CH2STW ro — The value of this register is derived from the DMAH_CH2_STW coreConsultant parameter.
        values as DMA.MISC.DMACOMPPARAMS5.CH5STW
      [2:0] CH2DTW ro — The value of this register is derived from the DMAH_CH2_DTW coreConsultant parameter.
        values as DMA.MISC.DMACOMPPARAMS5.CH5STW
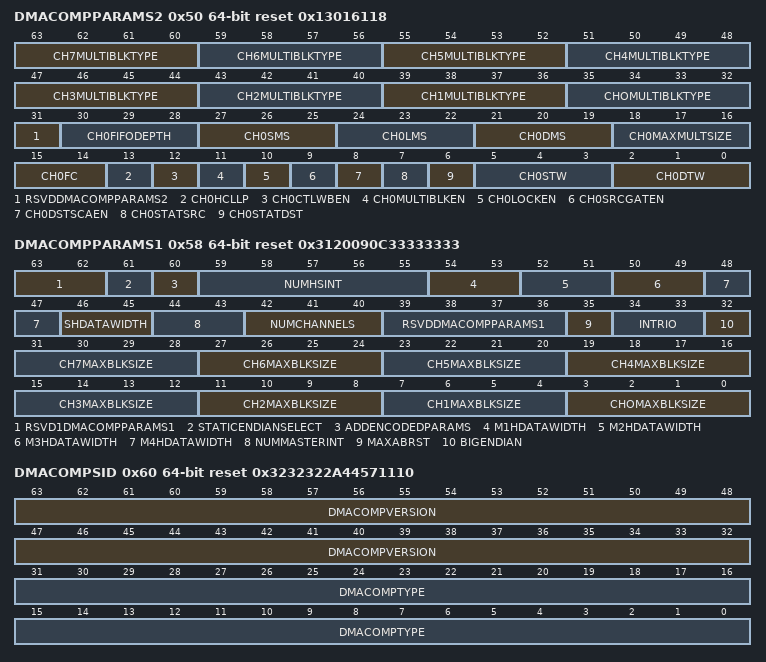
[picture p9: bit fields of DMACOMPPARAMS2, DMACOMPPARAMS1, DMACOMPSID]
    0x50 DMACOMPPARAMS2 64-bit reset 0x13016118 (reset mask 0xFFFFFFFF) — DMA_COMP_PARAMS_2 is a constant read-only register that contains encoded information about the component parameter settings.
      [4n+35:4n+32] CH{n}MULTIBLKTYPE ro (n=1..7) — The values of these bit fields are derived from the DMAH_CH{n}_MULTI_BLK_TYPE coreConsultant parameter.
        0=PROGRAMMABLE (Unspecified); 1=CONT_RELOAD (Unspecified); 2=RELOAD_CONT (Unspecified); 3=RELOAD_RELOAD (Unspecified); 4=CONT_LLP (Unspecified); 5=RELOAD_LLP (Unspecified); 6=CNT_LLP (Unspecified); 7=LLP_RELOAD (Unspecified); 8=LLP_LLP (Unspecified)
      [35:32] CHOMULTIBLKTYPE ro — The values of these bit fields are derived from the DMAH_CH0_MULTI_BLK_TYPE coreConsultant parameter.
        values as CH1MULTIBLKTYPE
      [31] RSVDDMACOMPPARAMS2 ro — Reserved field- read-only
      [30:28] CH0FIFODEPTH ro — The value of this register is derived from the DMAH_CH0_FIFO_DEPTH coreConsultant parameter.
        values as DMA.MISC.DMACOMPPARAMS6.CH7FIFODEPTH
      [27:25] CH0SMS ro — The value of this register is derived from the DMAH_CH0_SMS coreConsultant parameter.
        values as DMA.MISC.DMACOMPPARAMS6.CH7SMS
      [24:22] CH0LMS ro — The value of this register is derived from the DMAH_CH0_LMS coreConsultant parameter.
        values as DMA.MISC.DMACOMPPARAMS6.CH7SMS
      [21:19] CH0DMS ro — The value of this register is derived from the DMAH_CH0_DMS coreConsultant parameter.
        values as DMA.MISC.DMACOMPPARAMS6.CH7SMS
      [18:16] CH0MAXMULTSIZE ro — The value of this register is derived from the DMAH_CH0_MULT_SIZE coreConsultant parameter.
        values as DMA.MISC.DMACOMPPARAMS6.CH7MAXMULTSIZE
      [15:14] CH0FC ro — The value of this register is derived from the DMAH_CH0_FC coreConsultant parameter.
        values as DMA.MISC.DMACOMPPARAMS6.CH7FC
      [13] CH0HCLLP ro — The value of this register is derived from the DMAH_CH0_HC_LLP coreConsultant parameter.
        0=HARDCODED (Unspecified); 0=PROGRAMMABLE (Unspecified)
      [12] CH0CTLWBEN ro — The value of this register is derived from the DMAH_CH0_CTL_WB_EN coreConsultant parameter.
        0=FALSE (Unspecified); 1=TRUE (Unspecified)
      [11] CH0MULTIBLKEN ro — The value of this register is derived from the DMAH_CH0_MULTI_BLK_EN coreConsultant parameter.
        0=FALSE (Unspecified); 1=TRUE (Unspecified)
      [10] CH0LOCKEN ro — The value of this register is derived from the DMAH_CH0_LOCK_EN coreConsultant parameter.
        0=FALSE (Unspecified); 1=TRUE (Unspecified)
      [9] CH0SRCGATEN ro — The value of this register is derived from the DMAH_CH0_SRC_GAT_EN coreConsultant parameter.
        0=FALSE (Unspecified); 1=TRUE (Unspecified)
      [8] CH0DSTSCAEN ro — The value of this register is derived from the DMAH_CH0_DST_SCA_EN coreConsultant parameter.
        0=FALSE (Unspecified); 1=TRUE (Unspecified)
      [7] CH0STATSRC ro — The value of this register is derived from the DMAH_CH0_STAT_SRC coreConsultant parameter.
        0=FALSE (Unspecified); 1=TRUE (Unspecified)
      [6] CH0STATDST ro — The value of this register is derived from the DMAH_CH0_STAT_DST coreConsultant parameter.
        0=FALSE (Unspecified); 1=TRUE (Unspecified)
      [5:3] CH0STW ro — The value of this register is derived from the DMAH_CH0_STW coreConsultant parameter.
        values as DMA.MISC.DMACOMPPARAMS5.CH5STW
      [2:0] CH0DTW ro — The value of this register is derived from the DMAH_CH0_DTW coreConsultant parameter.
        values as DMA.MISC.DMACOMPPARAMS5.CH5STW
    0x58 DMACOMPPARAMS1 64-bit reset 0x3120090C33333333 (reset mask 0xFFFFFFFF) — DMA_COMP_PARAMS_1 is a constant read-only register that contains encoded information about the component parameter settings.
      [63:62] RSVD1DMACOMPPARAMS1 ro — Reserved field- read-only
      [61] STATICENDIANSELECT ro — The value of this register is derived from the DMAH_STATIC_ENDIAN_SELECT coreConsultant parameter.
      [60] ADDENCODEDPARAMS ro — The value of this register is derived from the DMAH_ADD_ENCODED_PARAMS coreConsultant parameter.
        0=FALSE (Unspecified); 0=STATIC_ENDIAN_FALSE (Unspecified); 1=STATIC_ENDIAN_TRUE (Unspecified); 1=TRUE (Unspecified)
      [59:55] NUMHSINT ro — The value of this register is derived from the DMAH_NUM_HS_INT coreConsultant parameter.
        {v}=HS_INTERFACE_{v} (Unspecified) (v=0..9); 10=HS_INTERFACE_a (Unspecified); 11=HS_INTERFACE_b (Unspecified); 12=HS_INTERFACE_c (Unspecified); 13=HS_INTERFACE_d (Unspecified); 14=HS_INTERFACE_e (Unspecified); 15=HS_INTERFACE_f (Unspecified); 16=HS_INTERFACE_10 (Unspecified)
      [56-2n:55-2n] M{n}HDATAWIDTH ro (n=1..4) — The value of this register is derived from the DMAH_M{n}_HDATA_WIDTH coreConsultant parameter.
        0=DATA_BUS_WIDTH_32 (Unspecified); 1=DATA_BUS_WIDTH_64 (Unspecified); 2=DATA_BUS_WIDTH_128 (Unspecified); 3=DATA_BUS_WIDTH_256 (Unspecified)
      [46:45] SHDATAWIDTH ro — The value of this register is derived from the DMAH_S_HDATA_WIDTH coreConsultant parameter.
        values as M1HDATAWIDTH
      [44:43] NUMMASTERINT ro — The value of this register is derived from the DMAH_NUM_MASTER_INT coreConsultant parameter.
        {v}=NUM_MST_INTERFACE_{v+1} (Unspecified) (v=0..3)
      [42:40] NUMCHANNELS ro — The value of this register is derived from the DMAH_NUM_CHANNELS coreConsultant parameter.
        {v}=NUM_CHANNEL_{v+1} (Unspecified) (v=0..7)
      [39:36] RSVDDMACOMPPARAMS1 ro — Reserved field- read-only
      [35] MAXABRST ro — The value of this register is derived from the DMAH_MABRST coreConsultant parameter.
        0=FALSE (Unspecified); 1=TRUE (Unspecified)
      [34:33] INTRIO ro — The value of this register is derived from the DMAH_INTR_IO coreConsultant parameter.
        0=ALL_INT (Unspecified); 1=TYPE_INT (Unspecified); 2=COMBINED_INT (Unspecified)
      [32] BIGENDIAN ro — The value of this register is derived from the DMAH_BIG_ENDIAN coreConsultant parameter.
        0=FALSE (Unspecified); 1=TRUE (Unspecified)
      [4n+3:4n] CH{n}MAXBLKSIZE ro (n=1..7) — The values of these bit fields are derived from the DMAH_CH{n}_MAX_BLK_SIZE coreConsultant parameter.
        0=MAX_BLOCK_SIZE_3 (Unspecified); 1=MAX_BLOCK_SIZE_7 (Unspecified); 2=MAX_BLOCK_SIZE_15 (Unspecified); 3=MAX_BLOCK_SIZE_31 (Unspecified); 4=MAX_BLOCK_SIZE_63 (Unspecified); 5=MAX_BLOCK_SIZE_127 (Unspecified); 6=MAX_BLOCK_SIZE_255 (Unspecified); 7=MAX_BLOCK_SIZE_511 (Unspecified); 8=MAX_BLOCK_SIZE_1023 (Unspecified); 9=MAX_BLOCK_SIZE_2047 (Unspecified); 10=MAX_BLOCK_SIZE_4095 (Unspecified)
      [3:0] CHOMAXBLKSIZE ro — The values of these bit fields are derived from the DMAH_CH0_MAX_BLK_SIZE coreConsultant parameter.
        values as CH1MAXBLKSIZE
    0x60 DMACOMPSID 64-bit reset 0x3232322A44571110 (reset mask 0xFFFFFFFF) — This is the DW_ahb_dmac Component Version register, which is a read-only register that specifies the version of the packaged component in the upper 32 bits and the component type in the lower 32 bits.
      [63:32] DMACOMPVERSION ro — DMA Component Version.
      [31:0] DMACOMPTYPE ro — DMA Component Type Number = `h44571110.

## Notices in the file
Copyright (c) 2010 - 2020, Nordic Semiconductor ASA
All rights reserved.
Redistribution and use in source and binary forms, with or without modification,
are permitted provided that the following conditions are met:
1. Redistributions of source code must retain the above copyright notice, this
list of conditions and the following disclaimer.
2. Redistributions in binary form, except as embedded into a Nordic
Semiconductor ASA integrated circuit in a product or a software update for
such product, must reproduce the above copyright notice, this list of
conditions and the following disclaimer in the documentation and/or other
materials provided with the distribution.
3. Neither the name of Nordic Semiconductor ASA nor the names of its
contributors may be used to endorse or promote products derived from this
software without specific prior written permission.
4. This software, with or without modification, must only be used with a
Nordic Semiconductor ASA integrated circuit.
5. Any software provided in binary form under this license must not be reverse
engineered, decompiled, modified and/or disassembled.
THIS SOFTWARE IS PROVIDED BY NORDIC SEMICONDUCTOR ASA "AS IS" AND ANY EXPRESS
OR IMPLIED WARRANTIES, INCLUDING, BUT NOT LIMITED TO, THE IMPLIED WARRANTIES
OF MERCHANTABILITY, NONINFRINGEMENT, AND FITNESS FOR A PARTICULAR PURPOSE ARE
DISCLAIMED. IN NO EVENT SHALL NORDIC SEMICONDUCTOR ASA OR CONTRIBUTORS BE
LIABLE FOR ANY DIRECT, INDIRECT, INCIDENTAL, SPECIAL, EXEMPLARY, OR
CONSEQUENTIAL DAMAGES (INCLUDING, BUT NOT LIMITED TO, PROCUREMENT OF SUBSTITUTE
GOODS OR SERVICES; LOSS OF USE, DATA, OR PROFITS; OR BUSINESS INTERRUPTION)
HOWEVER CAUSED AND ON ANY THEORY OF LIABILITY, WHETHER IN CONTRACT, STRICT
LIABILITY, OR TORT (INCLUDING NEGLIGENCE OR OTHERWISE) ARISING IN ANY WAY OUT
OF THE USE OF THIS SOFTWARE, EVEN IF ADVISED OF THE POSSIBILITY OF SUCH DAMAGE.
